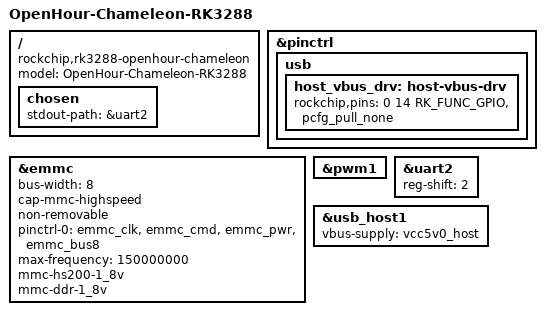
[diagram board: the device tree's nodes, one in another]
// SPDX-License-Identifier: GPL-2.0+ OR X11
/*
 * (C) Copyright 2016 Rockchip Electronics Co., Ltd
 */

/dts-v1/;
#include "rk3288-openhour-chameleon.dtsi"

/ {
	model = "OpenHour-Chameleon-RK3288";
	compatible = "rockchip,rk3288-openhour-chameleon", "rockchip,rk3288";

	chosen {
		stdout-path = &uart2;
	};
};

&pinctrl {
	usb {
		host_vbus_drv: host-vbus-drv {
			rockchip,pins = <0 14 RK_FUNC_GPIO &pcfg_pull_none>;
		};
	};
};

&emmc {
	bus-width = <8>;
	cap-mmc-highspeed;
	non-removable;
	pinctrl-names = "default";
	pinctrl-0 = <&emmc_clk &emmc_cmd &emmc_pwr &emmc_bus8>;
	max-frequency = <150000000>;
	mmc-hs200-1_8v;
	mmc-ddr-1_8v;
	status = "okay";
};

&pwm1 {
	status = "okay";
};

&uart2 {
	reg-shift = <2>;
};

&usb_host1 {
	vbus-supply = <&vcc5v0_host>;
	status = "okay";
};
